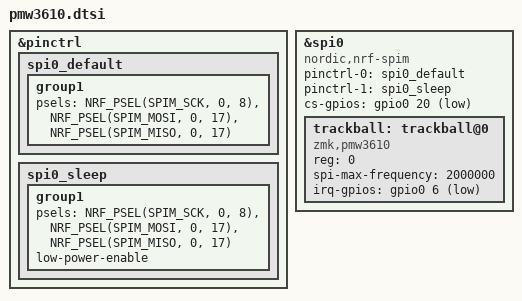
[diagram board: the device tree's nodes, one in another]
#include <physical_layouts.dtsi>

#include <behaviors.dtsi>
#include <dt-bindings/zmk/keys.h>
#include <dt-bindings/zmk/outputs.h>
#include <dt-bindings/zmk/mouse.h>
#include <dt-bindings/zmk/ext_power.h>

#include <dt-bindings/zmk/matrix_transform.h>
#include <input/processors.dtsi>
#include <zephyr/dt-bindings/input/input-event-codes.h>



 
/* 
    For the *peripheral* side that has SPI pointing device with it. Not even dongle.overlay should have this.
    What's here: pinctrl & trackball input device node (SPI) for right & dongle side.
*/


&pinctrl {
    spi0_default: spi0_default {
        group1 {
            psels = <NRF_PSEL(SPIM_SCK, 0, 8)>,
                <NRF_PSEL(SPIM_MOSI, 0, 17)>,
                <NRF_PSEL(SPIM_MISO, 0, 17)>;
        };
    };

    spi0_sleep: spi0_sleep {
        group1 {
            psels = <NRF_PSEL(SPIM_SCK, 0, 8)>,
                <NRF_PSEL(SPIM_MOSI, 0, 17)>,
                <NRF_PSEL(SPIM_MISO, 0, 17)>;
            low-power-enable;
        };
    };
};


#include <zephyr/dt-bindings/input/input-event-codes.h>
&spi0 {
    status = "okay";
    compatible = "nordic,nrf-spim";
    pinctrl-0 = <&spi0_default>;
    pinctrl-1 = <&spi0_sleep>;
    pinctrl-names = "default", "sleep";
    cs-gpios = <&gpio0 20 GPIO_ACTIVE_LOW>;

    trackball: trackball@0 {
        status = "okay";
        compatible = "zmk,pmw3610";
        reg = <0>;
        spi-max-frequency = <2000000>;
        irq-gpios = <&gpio0 6 (GPIO_ACTIVE_LOW | GPIO_PULL_UP)>;
        //cpi = <600>;
        //evt-type = <INPUT_EV_REL>;
        //x-input-code = <INPUT_REL_X>;
        //y-input-code = <INPUT_REL_Y>;
    };
};
                             

